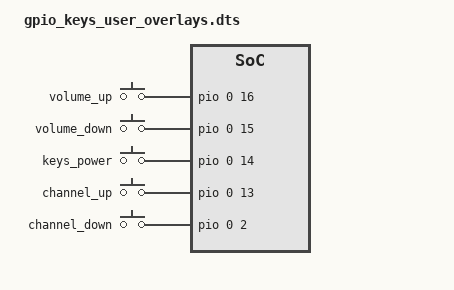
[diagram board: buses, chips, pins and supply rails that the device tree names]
&pio {
	gpio_keys_pins: gpio_keys_pins {
		pins = "PA13", "PA14", "PA15", "PA16", "PA2";
		function = "gpio_in";
		bias-pull-up;
		pull = <0x01>;
	};
};

/ {
	gpio_keys_user {
		compatible = "gpio-keys";
		pinctrl-names = "default";
		pinctrl-0 = <&gpio_keys_pins>;
		status = "okay";

		keys_volup {
			label = "volume_up";
			linux,code = <115>;
			gpios = <&pio 0 16 0>; 
		};

		keys_voldown {
			label = "volume_down";
			linux,code = <114>;
			gpios = <&pio 0 15 0>;
		};

		keys_power {
			label = "keys_power";
			linux,code = <116>;
			gpios = <&pio 0 14 0>;
		};

		keys_chanup {
			label = "channel_up";
			linux,code = <402>;
			gpios = <&pio 0 13 0>;
		};

		keys_chandown {
			label = "channel_down";
			linux,code = <403>;
			gpios = <&pio 0 2 0>;
		};
	};
};
